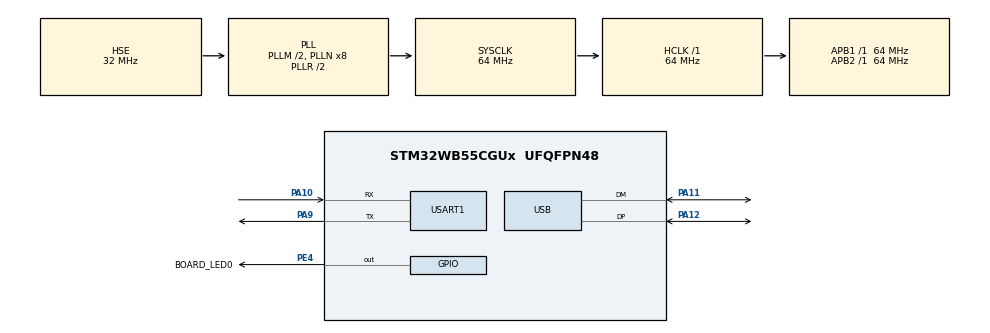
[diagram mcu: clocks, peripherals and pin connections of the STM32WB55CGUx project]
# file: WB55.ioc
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Mcu.Family=STM32WB
Mcu.Name=STM32WB55CGUx
Mcu.Package=UFQFPN48
Mcu.UserConstants=BOARD_UART1,$$_USART1_IP_HANDLE_$$
NVIC.HSEM_IRQn=true\:0\:0\:false\:false\:true\:false\:true\:true
NVIC.IPCC_C1_RX_IRQn=true\:0\:0\:false\:false\:true\:true\:true\:true
NVIC.IPCC_C1_TX_IRQn=true\:0\:0\:false\:false\:true\:true\:true\:true
NVIC.PriorityGroup=NVIC_PRIORITYGROUP_4
NVIC.RTC_WKUP_IRQn=true\:0\:0\:false\:false\:true\:true\:true\:true
NVIC.TIM1_TRG_COM_TIM17_IRQn=true\:15\:0\:false\:false\:true\:false\:true\:true
NVIC.TimeBase=TIM1_TRG_COM_TIM17_IRQn
NVIC.TimeBaseIP=TIM17
NVIC.USB_LP_IRQn=true\:0\:0\:false\:false\:true\:false\:true\:true
OSC_IN.Mode=HSE-External-Oscillator
OSC_IN.Signal=RCC_OSC_IN
OSC_OUT.Mode=HSE-External-Oscillator
OSC_OUT.Signal=RCC_OSC_OUT
PA10.Mode=Asynchronous
PA10.Signal=USART1_RX
PA11.Mode=Device
PA11.Signal=USB_DM
PA12.Mode=Device
PA12.Signal=USB_DP
PA13.Mode=Serial_Wire
PA13.Signal=SYS_JTMS-SWDIO
PA14.Mode=Serial_Wire
PA14.Signal=SYS_JTCK-SWCLK
PA9.Mode=Asynchronous
PA9.Signal=USART1_TX
PC14-OSC32_IN.Mode=LSE-External-Oscillator
PC14-OSC32_IN.Signal=RCC_OSC32_IN
PC15-OSC32_OUT.Mode=LSE-External-Oscillator
PC15-OSC32_OUT.Signal=RCC_OSC32_OUT
PE4.GPIO_Label=BOARD_LED0
PE4.Signal=GPIO_Output
ProjectManager.HeapSize=0x200
ProjectManager.StackSize=0x400
ProjectManager.TargetToolchain=STM32CubeIDE
RCC.ADCFreq_Value=48000000
RCC.AHB2CLKDivider=RCC_SYSCLK_DIV2
RCC.AHBFreq_Value=64000000
RCC.APB1Freq_Value=64000000
RCC.APB1TimFreq_Value=64000000
RCC.APB2Freq_Value=64000000
RCC.APB2TimFreq_Value=64000000
RCC.APB3Freq_Value=16000000
RCC.CortexFreq_Value=64000000
RCC.EnableCSSLSE=true
RCC.EnbaleCSS=true
RCC.HCLKFreq_Value=64000000
RCC.HSE_VALUE=32000000
RCC.HSI48_VALUE=48000000
RCC.HSI_VALUE=16000000
RCC.PLLM=RCC_PLLM_DIV2
RCC.PLLSAI1N=6
RCC.PLLSourceVirtual=RCC_PLLSOURCE_HSE
RCC.RTCClockSelection=RCC_RTCCLKSOURCE_LSE
RCC.SYSCLKFreq_VALUE=64000000
RCC.SYSCLKSource=RCC_SYSCLKSOURCE_PLLCLK
RCC.USBFreq_Value=48000000
RCC.VCOOutputFreq_Value=128000000
RF1.Mode=RF1_Activate
RF1.Signal=RF_RF1
STM32_WPAN.AD_TYPE_COMPLETE_LOCAL_NAME=ZotjinBLE
STM32_WPAN.AD_TYPE_COMPLETE_LOCAL_NAME_LENGTH=10
STM32_WPAN.AD_TYPE_MANUFACTURER_DATA_COMMENT_1=uf
STM32_WPAN.AD_TYPE_MANUFACTURER_SPECIFIC_DATA_COMPANY_IDENTIFIER=30,01
STM32_WPAN.AD_TYPE_SHORTENED_LOCAL_NAME=Zotja
STM32_WPAN.AD_TYPE_SHORTENED_LOCAL_NAME_LENGTH=6
STM32_WPAN.AD_TYPE_URI_DATA=www.kostic.cc
STM32_WPAN.AD_TYPE_URI_DATA_LENGTH=13
STM32_WPAN.CFG_LSCLK_LSE=0
STM32_WPAN.CFG_TX_POWER=(0x11) /* -4dBm */
STM32_WPAN.INCLUDE_AD_TYPE_128_BIT_SERV_UUID_CMPLT_LIST=0
STM32_WPAN.INCLUDE_AD_TYPE_ADVERTISING_INTERVAL=0
STM32_WPAN.INCLUDE_AD_TYPE_APPEARANCE=0
STM32_WPAN.INCLUDE_AD_TYPE_COMPLETE_LOCAL_NAME=1
STM32_WPAN.INCLUDE_AD_TYPE_LE_ROLE=0
STM32_WPAN.INCLUDE_AD_TYPE_MANUFACTURER_SPECIFIC_DATA=0
STM32_WPAN.INCLUDE_AD_TYPE_SHORTENED_LOCAL_NAME=0
STM32_WPAN.INCLUDE_AD_TYPE_SLAVE_CONN_INTERVAL=0
STM32_WPAN.INCLUDE_AD_TYPE_TX_POWER_LEVEL=1
STM32_WPAN.INCLUDE_AD_TYPE_URI=0
STM32_WPAN.LOCAL_NAME_FORMATTED=,'S','T','M','3','2','W','B'
STM32_WPAN.NUMBER_OF_SERVICES=3
STM32_WPAN.SERVICE1_CHAR1_GATT_NOTIFY_READ_REQ_AND_WAIT_FOR_APPL_RESP=\ 
STM32_WPAN.SERVICE1_CHAR1_GATT_NOTIFY_WRITE_REQ_AND_WAIT_FOR_APPL_RESP=\ 
STM32_WPAN.SERVICE1_CHAR1_LENGTH_CHARACTERISTIC=CHAR_VALUE_LEN_VARIABLE
STM32_WPAN.SERVICE1_CHAR1_LONG_NAME=charWrite
STM32_WPAN.SERVICE1_CHAR1_PROP_WRITE=CHAR_PROP_WRITE
STM32_WPAN.SERVICE1_CHAR1_SHORT_NAME=charWrite
STM32_WPAN.SERVICE1_CHAR1_VALUE_LENGTH=512
STM32_WPAN.SERVICE1_LONG_NAME=zSvcA
STM32_WPAN.SERVICE1_SHORT_NAME=zSA
STM32_WPAN.SERVICE2_CHAR1_GATT_NOTIFY_READ_REQ_AND_WAIT_FOR_APPL_RESP=\ 
STM32_WPAN.SERVICE2_CHAR1_GATT_NOTIFY_WRITE_REQ_AND_WAIT_FOR_APPL_RESP=\ 
STM32_WPAN.SERVICE2_CHAR1_LONG_NAME=svcB1
STM32_WPAN.SERVICE2_CHAR1_PROP_BROADCAST=CHAR_PROP_BROADCAST
STM32_WPAN.SERVICE2_CHAR1_PROP_READ=CHAR_PROP_READ
STM32_WPAN.SERVICE2_CHAR1_PROP_WRITE=CHAR_PROP_WRITE
STM32_WPAN.SERVICE2_CHAR1_SHORT_NAME=svcB1
STM32_WPAN.SERVICE2_CHAR2_GATT_NOTIFY_READ_REQ_AND_WAIT_FOR_APPL_RESP=\ 
STM32_WPAN.SERVICE2_CHAR2_GATT_NOTIFY_WRITE_REQ_AND_WAIT_FOR_APPL_RESP=\ 
STM32_WPAN.SERVICE2_CHAR2_LENGTH_CHARACTERISTIC=CHAR_VALUE_LEN_VARIABLE
STM32_WPAN.SERVICE2_CHAR2_LONG_NAME=svcB2
STM32_WPAN.SERVICE2_CHAR2_SHORT_NAME=svcB2
STM32_WPAN.SERVICE2_LONG_NAME=zSvcB
STM32_WPAN.SERVICE2_NUMBER_OF_CHARACTERISTICS=2
STM32_WPAN.SERVICE2_SHORT_NAME=zSB
STM32_WPAN.SERVICE2_TYPE=SECONDARY_SERVICE
STM32_WPAN.SERVICE3_CHAR1_GATT_NOTIFY_READ_REQ_AND_WAIT_FOR_APPL_RESP=\ 
STM32_WPAN.SERVICE3_CHAR1_GATT_NOTIFY_WRITE_REQ_AND_WAIT_FOR_APPL_RESP=\ 
STM32_WPAN.SERVICE3_CHAR1_LONG_NAME=uart_tx
STM32_WPAN.SERVICE3_CHAR1_SHORT_NAME=uart_tx
STM32_WPAN.SERVICE3_CHAR2_GATT_NOTIFY_READ_REQ_AND_WAIT_FOR_APPL_RESP=\ 
STM32_WPAN.SERVICE3_CHAR2_GATT_NOTIFY_WRITE_REQ_AND_WAIT_FOR_APPL_RESP=\ 
STM32_WPAN.SERVICE3_CHAR2_LONG_NAME=uart_rx
STM32_WPAN.SERVICE3_CHAR2_SHORT_NAME=uart_rx
STM32_WPAN.SERVICE3_LONG_NAME=zGATT_UART
STM32_WPAN.SERVICE3_NUMBER_OF_CHARACTERISTICS=2
STM32_WPAN.SERVICE3_SHORT_NAME=zUART
USART1.VirtualMode-Asynchronous=VM_ASYNC
USB_DEVICE.CLASS_NAME_FS=CDC
USB_DEVICE.VirtualMode=Cdc
USB_DEVICE.VirtualModeFS=Cdc_FS
VP_HSEM_VS_HSEM.Mode=HSEM_Activate
VP_IPCC_VS_IPCC.Mode=IPCC_Activate
VP_MEMORYMAP_VS_MEMORYMAP.Mode=CurAppReg
VP_RTC_VS_RTC_Activate.Mode=RTC_Enabled
VP_RTC_VS_RTC_WakeUp_intern.Mode=WakeUp
VP_SEQUENCER_VS_SEQUENCER.Mode=SEQUENCER_Enabled
VP_STM32_WPAN_VS_BLE_HOST.Mode=STM32_WPAN_Enabled
VP_SYS_VS_tim17.Mode=TIM17
VP_TINY_LPM_VS_TINY_LPM.Mode=TINY_LPM_Enabled
VP_USB_DEVICE_VS_USB_DEVICE_CDC_FS.Mode=CDC_FS
board=custom

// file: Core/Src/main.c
/* USER CODE BEGIN Header */
/**
  ******************************************************************************
  * @file           : main.c
  * @brief          : Main program body
  ******************************************************************************
  * @attention
  *
  * Copyright (c) 2024 STMicroelectronics.
  * All rights reserved.
  *
  * This software is licensed under terms that can be found in the LICENSE file
  * in the root directory of this software component.
  * If no LICENSE file comes with this software, it is provided AS-IS.
  *
  ******************************************************************************
  */
/* USER CODE END Header */
#include "main.h"
#include "usb_device.h"

IPCC_HandleTypeDef hipcc;

RTC_HandleTypeDef hrtc;

UART_HandleTypeDef huart1;

void SystemClock_Config(void);
void PeriphCommonClock_Config(void);
static void MX_GPIO_Init(void);
static void MX_IPCC_Init(void);
static void MX_RTC_Init(void);
static void MX_USART1_UART_Init(void);
static void MX_RF_Init(void);

int main(void)
{

  /* MCU Configuration--------------------------------------------------------*/

  /* Reset of all peripherals, Initializes the Flash interface and the Systick. */
  HAL_Init();
  /* Config code for STM32_WPAN (HSE Tuning must be done before system clock configuration) */
  MX_APPE_Config();

  /* Configure the system clock */
  SystemClock_Config();

  /* Configure the peripherals common clocks */
  PeriphCommonClock_Config();

  /* IPCC initialisation */
  MX_IPCC_Init();

  /* Initialize all configured peripherals */
  MX_GPIO_Init();
  MX_USB_Device_Init();
  MX_RTC_Init();
  MX_USART1_UART_Init();
  MX_RF_Init();

  /* Init code for STM32_WPAN */
  MX_APPE_Init();

  /* Infinite loop */
  while (1)
  {
    MX_APPE_Process();

  }
}

void SystemClock_Config(void)
{
  RCC_OscInitTypeDef RCC_OscInitStruct = {0};
  RCC_ClkInitTypeDef RCC_ClkInitStruct = {0};

  /** Configure LSE Drive Capability
  */
  HAL_PWR_EnableBkUpAccess();
  __HAL_RCC_LSEDRIVE_CONFIG(RCC_LSEDRIVE_MEDIUMHIGH);

  /** Configure the main internal regulator output voltage
  */
  __HAL_PWR_VOLTAGESCALING_CONFIG(PWR_REGULATOR_VOLTAGE_SCALE1);

  /** Initializes the RCC Oscillators according to the specified parameters
  * in the RCC_OscInitTypeDef structure.
  */
  RCC_OscInitStruct.OscillatorType = RCC_OSCILLATORTYPE_HSI|RCC_OSCILLATORTYPE_HSE
                              |RCC_OSCILLATORTYPE_LSE;
  RCC_OscInitStruct.HSEState = RCC_HSE_ON;
  RCC_OscInitStruct.LSEState = RCC_LSE_ON;
  RCC_OscInitStruct.HSIState = RCC_HSI_ON;
  RCC_OscInitStruct.HSICalibrationValue = RCC_HSICALIBRATION_DEFAULT;
  RCC_OscInitStruct.PLL.PLLState = RCC_PLL_ON;
  RCC_OscInitStruct.PLL.PLLSource = RCC_PLLSOURCE_HSE;
  RCC_OscInitStruct.PLL.PLLM = RCC_PLLM_DIV2;
  RCC_OscInitStruct.PLL.PLLN = 8;
  RCC_OscInitStruct.PLL.PLLP = RCC_PLLP_DIV2;
  RCC_OscInitStruct.PLL.PLLR = RCC_PLLR_DIV2;
  RCC_OscInitStruct.PLL.PLLQ = RCC_PLLQ_DIV2;
  if (HAL_RCC_OscConfig(&RCC_OscInitStruct) != HAL_OK)
  {
    Error_Handler();
  }

  /** Configure the SYSCLKSource, HCLK, PCLK1 and PCLK2 clocks dividers
  */
  RCC_ClkInitStruct.ClockType = RCC_CLOCKTYPE_HCLK4|RCC_CLOCKTYPE_HCLK2
                              |RCC_CLOCKTYPE_HCLK|RCC_CLOCKTYPE_SYSCLK
                              |RCC_CLOCKTYPE_PCLK1|RCC_CLOCKTYPE_PCLK2;
  RCC_ClkInitStruct.SYSCLKSource = RCC_SYSCLKSOURCE_PLLCLK;
  RCC_ClkInitStruct.AHBCLKDivider = RCC_SYSCLK_DIV1;
  RCC_ClkInitStruct.APB1CLKDivider = RCC_HCLK_DIV1;
  RCC_ClkInitStruct.APB2CLKDivider = RCC_HCLK_DIV1;
  RCC_ClkInitStruct.AHBCLK2Divider = RCC_SYSCLK_DIV2;
  RCC_ClkInitStruct.AHBCLK4Divider = RCC_SYSCLK_DIV1;

  if (HAL_RCC_ClockConfig(&RCC_ClkInitStruct, FLASH_LATENCY_3) != HAL_OK)
  {
    Error_Handler();
  }

  /** Enables the Clock Security System
  */
  HAL_RCC_EnableCSS();

  /** Enables the Clock Security System
  */
  HAL_RCCEx_EnableLSECSS();
}

void PeriphCommonClock_Config(void)
{
  RCC_PeriphCLKInitTypeDef PeriphClkInitStruct = {0};

  /** Initializes the peripherals clock
  */
  PeriphClkInitStruct.PeriphClockSelection = RCC_PERIPHCLK_SMPS|RCC_PERIPHCLK_RFWAKEUP;
  PeriphClkInitStruct.RFWakeUpClockSelection = RCC_RFWKPCLKSOURCE_HSE_DIV1024;
  PeriphClkInitStruct.SmpsClockSelection = RCC_SMPSCLKSOURCE_HSI;
  PeriphClkInitStruct.SmpsDivSelection = RCC_SMPSCLKDIV_RANGE1;

  if (HAL_RCCEx_PeriphCLKConfig(&PeriphClkInitStruct) != HAL_OK)
  {
    Error_Handler();
  }
  /* USER CODE BEGIN Smps */

  	  //  OVO OVO USB device descriptor failed!!
  	  //  Phil's LAB Phil Salmony
  	  //  https://youtu.be/-xYoI84zJew?t=1616
  	  //    LL_HSEM_1StepLock( HSEM, 5 );
  	  // https://community.st.com/t5/stm32-mcus-wireless/usb-device-does-not-work-when-starting-ble-stack-on-stm32wb55/td-p/176360

  	  LL_HSEM_1StepLock( HSEM, 5 );

  /* USER CODE END Smps */
}

static void MX_IPCC_Init(void)
{

  hipcc.Instance = IPCC;
  if (HAL_IPCC_Init(&hipcc) != HAL_OK)
  {
    Error_Handler();
  }

}

static void MX_RF_Init(void)
{

}

static void MX_RTC_Init(void)
{

  /** Initialize RTC Only
  */
  hrtc.Instance = RTC;
  hrtc.Init.HourFormat = RTC_HOURFORMAT_24;
  hrtc.Init.AsynchPrediv = CFG_RTC_ASYNCH_PRESCALER;
  hrtc.Init.SynchPrediv = CFG_RTC_SYNCH_PRESCALER;
  hrtc.Init.OutPut = RTC_OUTPUT_DISABLE;
  hrtc.Init.OutPutPolarity = RTC_OUTPUT_POLARITY_HIGH;
  hrtc.Init.OutPutType = RTC_OUTPUT_TYPE_OPENDRAIN;
  hrtc.Init.OutPutRemap = RTC_OUTPUT_REMAP_NONE;
  if (HAL_RTC_Init(&hrtc) != HAL_OK)
  {
    Error_Handler();
  }

  /** Enable the WakeUp
  */
  if (HAL_RTCEx_SetWakeUpTimer_IT(&hrtc, 0, RTC_WAKEUPCLOCK_RTCCLK_DIV16) != HAL_OK)
  {
    Error_Handler();
  }

}

static void MX_USART1_UART_Init(void)
{

  huart1.Instance = USART1;
  huart1.Init.BaudRate = 115200;
  huart1.Init.WordLength = UART_WORDLENGTH_8B;
  huart1.Init.StopBits = UART_STOPBITS_1;
  huart1.Init.Parity = UART_PARITY_NONE;
  huart1.Init.Mode = UART_MODE_TX_RX;
  huart1.Init.HwFlowCtl = UART_HWCONTROL_NONE;
  huart1.Init.OverSampling = UART_OVERSAMPLING_16;
  huart1.Init.OneBitSampling = UART_ONE_BIT_SAMPLE_DISABLE;
  huart1.Init.ClockPrescaler = UART_PRESCALER_DIV1;
  huart1.AdvancedInit.AdvFeatureInit = UART_ADVFEATURE_NO_INIT;
  if (HAL_UART_Init(&huart1) != HAL_OK)
  {
    Error_Handler();
  }
  if (HAL_UARTEx_SetTxFifoThreshold(&huart1, UART_TXFIFO_THRESHOLD_1_8) != HAL_OK)
  {
    Error_Handler();
  }
  if (HAL_UARTEx_SetRxFifoThreshold(&huart1, UART_RXFIFO_THRESHOLD_1_8) != HAL_OK)
  {
    Error_Handler();
  }
  if (HAL_UARTEx_DisableFifoMode(&huart1) != HAL_OK)
  {
    Error_Handler();
  }

}

static void MX_GPIO_Init(void)
{
  GPIO_InitTypeDef GPIO_InitStruct = {0};

  /* GPIO Ports Clock Enable */
  __HAL_RCC_GPIOC_CLK_ENABLE();
  __HAL_RCC_GPIOA_CLK_ENABLE();
  __HAL_RCC_GPIOE_CLK_ENABLE();

  /*Configure GPIO pin Output Level */
  HAL_GPIO_WritePin(BOARD_LED0_GPIO_Port, BOARD_LED0_Pin, GPIO_PIN_RESET);

  /*Configure GPIO pin : BOARD_LED0_Pin */
  GPIO_InitStruct.Pin = BOARD_LED0_Pin;
  GPIO_InitStruct.Mode = GPIO_MODE_OUTPUT_PP;
  GPIO_InitStruct.Pull = GPIO_NOPULL;
  GPIO_InitStruct.Speed = GPIO_SPEED_FREQ_LOW;
  HAL_GPIO_Init(BOARD_LED0_GPIO_Port, &GPIO_InitStruct);

}

void HAL_TIM_PeriodElapsedCallback(TIM_HandleTypeDef *htim)
{
  if (htim->Instance == TIM17)
  {
    HAL_IncTick();
  }
}

void Error_Handler(void)
{
  __disable_irq();
  while (1)
  {
  }
}
